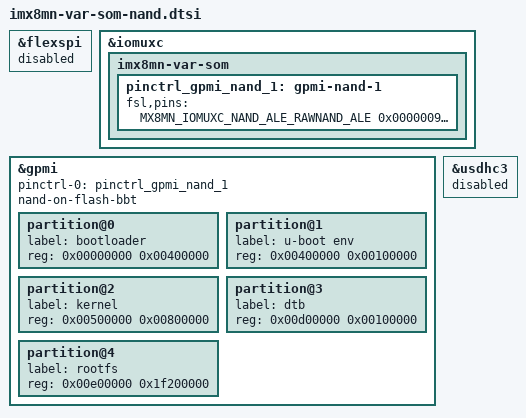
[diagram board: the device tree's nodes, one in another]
/*
 * Copyright 2018-2019 NXP
 * Copyright 2022 Variscite Ltd.
 *
 * This program is free software; you can redistribute it and/or
 * modify it under the terms of the GNU General Public License
 * as published by the Free Software Foundation; either version 2
 * of the License, or (at your option) any later version.
 *
 * This program is distributed in the hope that it will be useful,
 * but WITHOUT ANY WARRANTY; without even the implied warranty of
 * MERCHANTABILITY or FITNESS FOR A PARTICULAR PURPOSE.  See the
 * GNU General Public License for more details.
 */

&flexspi {
	status = "disabled";
};

&iomuxc {
	imx8mn-var-som {
		pinctrl_gpmi_nand_1: gpmi-nand-1 {
			fsl,pins = <
				MX8MN_IOMUXC_NAND_ALE_RAWNAND_ALE		0x00000096
				MX8MN_IOMUXC_NAND_CE0_B_RAWNAND_CE0_B		0x00000096
				MX8MN_IOMUXC_NAND_CE1_B_RAWNAND_CE1_B		0x00000096
				MX8MN_IOMUXC_NAND_CLE_RAWNAND_CLE		0x00000096
				MX8MN_IOMUXC_NAND_DATA00_RAWNAND_DATA00		0x00000096
				MX8MN_IOMUXC_NAND_DATA01_RAWNAND_DATA01		0x00000096
				MX8MN_IOMUXC_NAND_DATA02_RAWNAND_DATA02		0x00000096
				MX8MN_IOMUXC_NAND_DATA03_RAWNAND_DATA03		0x00000096
				MX8MN_IOMUXC_NAND_DATA04_RAWNAND_DATA04		0x00000096
				MX8MN_IOMUXC_NAND_DATA05_RAWNAND_DATA05		0x00000096
				MX8MN_IOMUXC_NAND_DATA06_RAWNAND_DATA06		0x00000096
				MX8MN_IOMUXC_NAND_DATA07_RAWNAND_DATA07		0x00000096
				MX8MN_IOMUXC_NAND_RE_B_RAWNAND_RE_B		0x00000096
				MX8MN_IOMUXC_NAND_READY_B_RAWNAND_READY_B	0x00000056
				MX8MN_IOMUXC_NAND_WE_B_RAWNAND_WE_B		0x00000096
				MX8MN_IOMUXC_NAND_WP_B_RAWNAND_WP_B		0x00000096
			>;
		};
	};
};

/* NAND flash */
&gpmi {
	pinctrl-names = "default";
	pinctrl-0 = <&pinctrl_gpmi_nand_1>;
	nand-on-flash-bbt;
	status = "okay";

	/* 4 MiB bootloader partition */
	partition@0 {
		label = "bootloader";
		reg = <0x00000000 0x00400000>;
	};

	/* 1 MiB U-Boot env partition */
	partition@1 {
		label = "u-boot env";
		reg = <0x00400000 0x00100000>;
	};

	/* 8 MiB kernel partition */
	partition@2 {
		label = "kernel";
		reg = <0x00500000 0x00800000>;
	};

	/* 1 MiB DTB partition */
	partition@3 {
		label = "dtb";
		reg = <0x00d00000 0x00100000>;
	};

	/* Rootfs partition */
	partition@4 {
		label = "rootfs";
		reg = <0x00e00000 0x1f200000>;
	};
};

/* eMMC */
&usdhc3 {
	status = "disabled";
};
